# ATSAMA5D34 register map
Vendor: Microchip Technology; Series: SAMA5D3; File version: 0
Registers are 32-bit, read-write, reset 0x0 unless marked. A register's access mark holds for its fields unless they carry their own. Offsets are from the block's base; [hi:lo] are bit positions.

## TWI0 — Two-wire Interface
Base 0xF0014000; register names take the prefix TWI_
Same registers: TWI1 0xF0018000, TWI2 0xF801C000
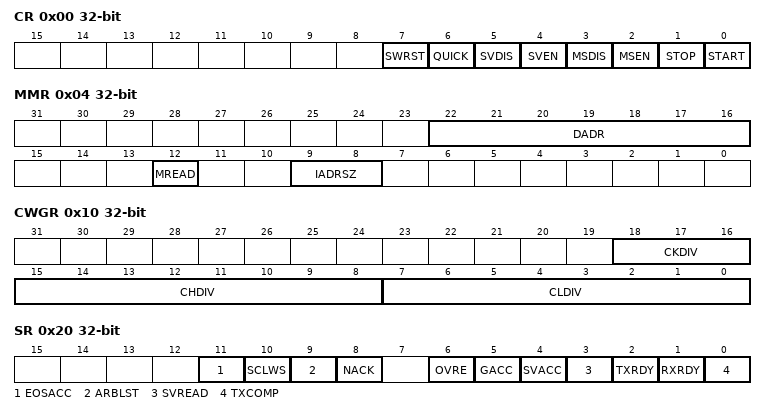
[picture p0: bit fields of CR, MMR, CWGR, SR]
0x00 CR wo — Control Register
  [7] SWRST — Software Reset
  [6] QUICK — SMBus Quick Command
  [5] SVDIS — TWI Slave Mode Disabled
  [4] SVEN — TWI Slave Mode Enabled
  [3] MSDIS — TWI Master Mode Disabled
  [2] MSEN — TWI Master Mode Enabled
  [1] STOP — Send a STOP Condition
  [0] START — Send a START Condition
0x04 MMR — Master Mode Register
  [22:16] DADR — Device Address
  [12] MREAD — Master Read Direction
  [9:8] IADRSZ — Internal Device Address Size
    0=NONE (No internal device address); 1=_1_BYTE (One-byte internal device address); 2=_2_BYTE (Two-byte internal device address); 3=_3_BYTE (Three-byte internal device address)
0x08 SMR — Slave Mode Register
  [22:16] SADR — Slave Address
0x0C IADR — Internal Address Register
  [23:0] IADR — Internal Address
0x10 CWGR — Clock Waveform Generator Register
  [18:16] CKDIV — Clock Divider
  [15:8] CHDIV — Clock High Divider
  [7:0] CLDIV — Clock Low Divider
0x20 SR ro — Status Register
  [11] EOSACC — End Of Slave Access (cleared on read)
  [10] SCLWS — Clock Wait State
  [9] ARBLST — Arbitration Lost (cleared on read)
  [8] NACK — Not Acknowledged (cleared on read)
  [6] OVRE — Overrun Error (cleared on read)
  [5] GACC — General Call Access (cleared on read)
  [4] SVACC — Slave Access
  [3] SVREAD — Slave Read
  [2] TXRDY — Transmit Holding Register Ready (cleared by writing TWI_THR)
  [1] RXRDY — Receive Holding Register Ready (cleared by reading TWI_RHR)
  [0] TXCOMP — Transmission Completed (cleared by writing TWI_THR)
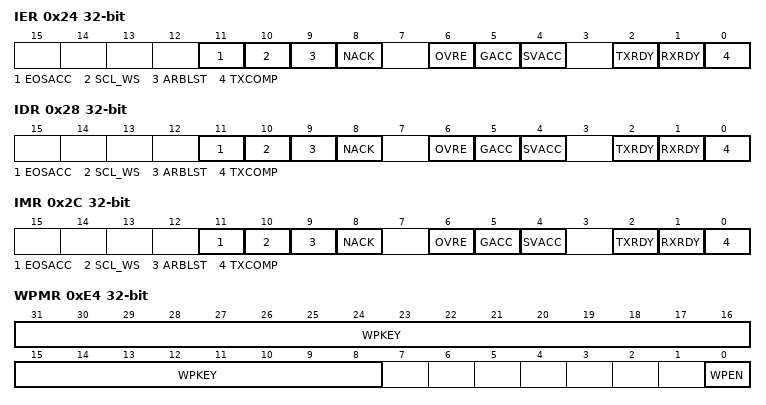
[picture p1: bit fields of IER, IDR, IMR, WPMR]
0x24 IER wo — Interrupt Enable Register
  [11] EOSACC — End Of Slave Access Interrupt Enable
  [10] SCL_WS — Clock Wait State Interrupt Enable
  [9] ARBLST — Arbitration Lost Interrupt Enable
  [8] NACK — Not Acknowledge Interrupt Enable
  [6] OVRE — Overrun Error Interrupt Enable
  [5] GACC — General Call Access Interrupt Enable
  [4] SVACC — Slave Access Interrupt Enable
  [2] TXRDY — Transmit Holding Register Ready Interrupt Enable
  [1] RXRDY — Receive Holding Register Ready Interrupt Enable
  [0] TXCOMP — Transmission Completed Interrupt Enable
0x28 IDR wo — Interrupt Disable Register
  [11] EOSACC — End Of Slave Access Interrupt Disable
  [10] SCL_WS — Clock Wait State Interrupt Disable
  [9] ARBLST — Arbitration Lost Interrupt Disable
  [8] NACK — Not Acknowledge Interrupt Disable
  [6] OVRE — Overrun Error Interrupt Disable
  [5] GACC — General Call Access Interrupt Disable
  [4] SVACC — Slave Access Interrupt Disable
  [2] TXRDY — Transmit Holding Register Ready Interrupt Disable
  [1] RXRDY — Receive Holding Register Ready Interrupt Disable
  [0] TXCOMP — Transmission Completed Interrupt Disable
0x2C IMR ro — Interrupt Mask Register
  [11] EOSACC — End Of Slave Access Interrupt Mask
  [10] SCL_WS — Clock Wait State Interrupt Mask
  [9] ARBLST — Arbitration Lost Interrupt Mask
  [8] NACK — Not Acknowledge Interrupt Mask
  [6] OVRE — Overrun Error Interrupt Mask
  [5] GACC — General Call Access Interrupt Mask
  [4] SVACC — Slave Access Interrupt Mask
  [2] TXRDY — Transmit Holding Register Ready Interrupt Mask
  [1] RXRDY — Receive Holding Register Ready Interrupt Mask
  [0] TXCOMP — Transmission Completed Interrupt Mask
0x30 RHR ro — Receive Holding Register
  [7:0] RXDATA — Master or Slave Receive Holding Data
0x34 THR wo — Transmit Holding Register
  [7:0] TXDATA — Master or Slave Transmit Holding Data
0xE4 WPMR — Write Protection Mode Register
  [31:8] WPKEY — Write Protection Key
    0x545749=PASSWD (Writing any other value in this field aborts the write operation of the WPEN bit.Always reads as 0)
  [0] WPEN — Write Protection Enable
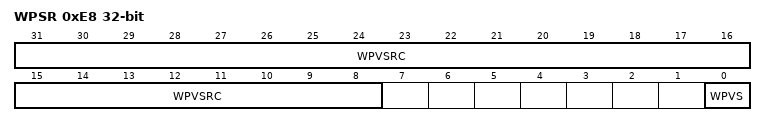
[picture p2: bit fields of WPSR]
0xE8 WPSR ro — Write Protection Status Register
  [31:8] WPVSRC — Write Protection Violation Source
  [0] WPVS — Write Protection Violation Status
